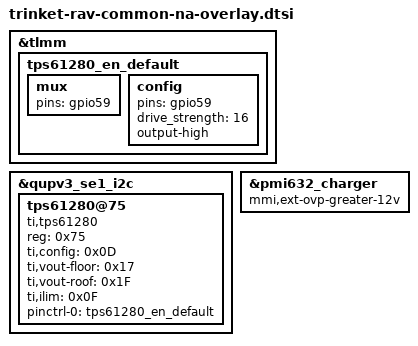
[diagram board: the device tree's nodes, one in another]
/* Copyright (c) 2019, The Linux Foundation. All rights reserved.
 *
 * This program is free software; you can redistribute it and/or modify
 * it under the terms of the GNU General Public License version 2 and
 * only version 2 as published by the Free Software Foundation.
 *
 * This program is distributed in the hope that it will be useful,
 * but WITHOUT ANY WARRANTY; without even the implied warranty of
 * MERCHANTABILITY or FITNESS FOR A PARTICULAR PURPOSE.  See the
 * GNU General Public License for more details.
 */

#include "trinket-rav-common-overlay.dtsi"
#include "trinket-rav-sensor-na-overlay.dtsi"

&tlmm {
    tps61280_en_default: tps61280_en_default {
		mux {
				pins = "gpio59";
		};
		config {
				pins = "gpio59";
				drive_strength = <16>;
				output-high;
		};
    };
};

&qupv3_se1_i2c {
	status = "ok";
	tps61280@75 {
		compatible = "ti,tps61280";
		reg = <0x75>;
		ti,config = <0x0D>;
		ti,vout-floor = <0x17>;
		ti,vout-roof = <0x1F>;
		ti,ilim = <0x0F>;
		pinctrl-names = "default";
		pinctrl-0 = <&tps61280_en_default>;
	};
};

&pmi632_charger {
	mmi,ext-ovp-greater-12v;
};
